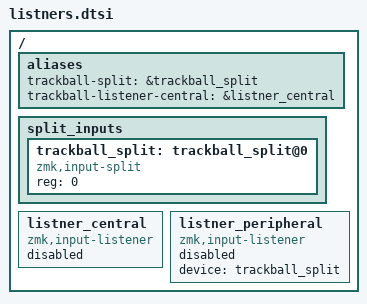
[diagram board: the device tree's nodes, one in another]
/{
  aliases {
    trackball-split = &trackball_split;
    trackball-listener-central = &listner_central;
  };

  split_inputs {
    #address-cells = <1>;
    #size-cells = <0>;
    
    trackball_split: trackball_split@0 {
      compatible = "zmk,input-split";
      reg = <0>;
    };
  };
    
  listner_central: listner_central {
    compatible = "zmk,input-listener";
    status = "disabled";
  };
    
  listner_peripheral: listner_peripheral {
    compatible = "zmk,input-listener";
    status = "disabled";
    device = <&trackball_split>;
  };
    
};
